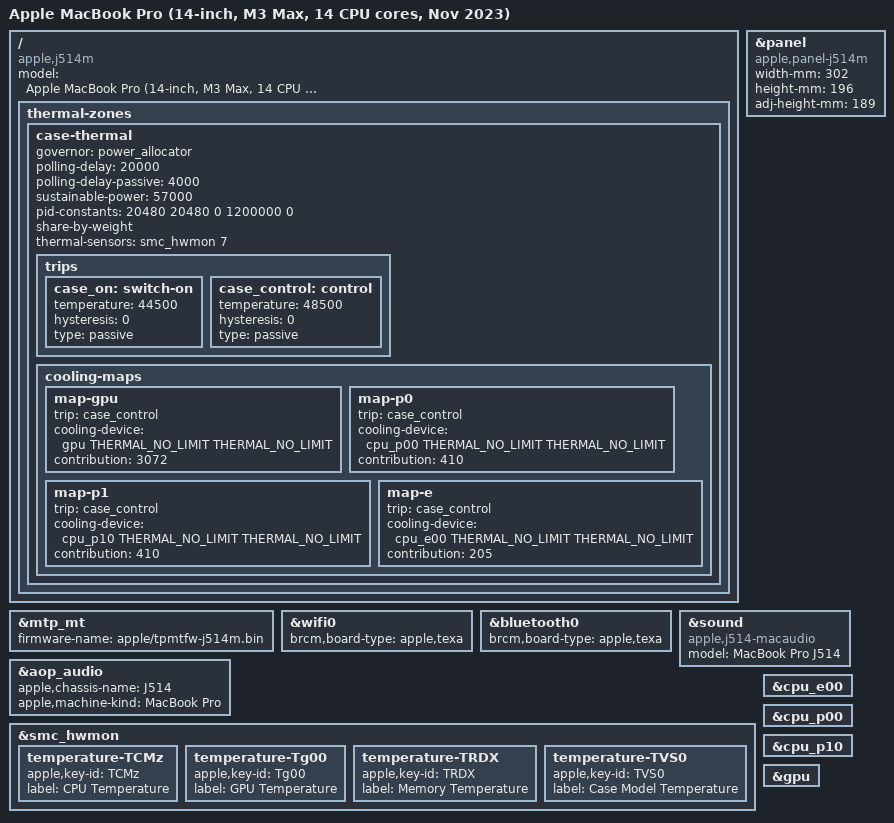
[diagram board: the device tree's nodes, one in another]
// SPDX-License-Identifier: GPL-2.0+ OR MIT
/*
 * MacBook Pro (14-inch, M3 Max, 14 CPU cores, Nov 2023)
 *
 * target-type: J514m
 *
 * Copyright The Asahi Linux Contributors
 */

/dts-v1/;

#include <dt-bindings/thermal/thermal.h>
#include "t6034.dtsi"
#include "t603x-j514-j516.dtsi"
#include "t6031-j514-j516.dtsi"

/ {
	compatible = "apple,j514m", "apple,t6034", "apple,arm-platform";
	model = "Apple MacBook Pro (14-inch, M3 Max, 14 CPU cores, Nov 2023)";
};

&panel {
	compatible = "apple,panel-j514m", "apple,panel-mini-led", "apple,panel";
	width-mm = <302>;
	height-mm = <196>;
	adj-height-mm = <189>;
};

&mtp_mt {
	firmware-name = "apple/tpmtfw-j514m.bin";
};

&wifi0 {
	brcm,board-type = "apple,texa";
};

&bluetooth0 {
	brcm,board-type = "apple,texa";
};

&aop_audio {
	apple,chassis-name = "J514";
	apple,machine-kind = "MacBook Pro";
};

&sound {
	compatible = "apple,j514-macaudio", "apple,j314-macaudio", "apple,macaudio";
	model = "MacBook Pro J514";
};

&smc_hwmon {
	#thermal-sensor-cells = <1>;

	/*
	 * The CPU's and the GPU's temperatures (read on this Mac, 2026-11-02):
	 * TCMz follows the P cores (+16 C for one busy core, +24 C for all ten)
	 * and sits above every P-core die sensor (Tp**), so the clusters' max
	 * (inferred); Tg00 is the first of the GPU die's 16 sensor pairs, 0 while
	 * the GPU is powered off, 61-64 C with every pair under a GPU load.
	 */
	temperature-TCMz {
		apple,key-id = "TCMz";
		label = "CPU Temperature";
	};

	temperature-Tg00 {
		apple,key-id = "Tg00";
		label = "GPU Temperature";
	};

	/*
	 * The hottest of the memory's sensors, and the SMC's model of the case
	 * (read as such; it lags the fast sensors by about 200 s). The SMC slows
	 * the GPU to 618 MHz and the whole Mac to about 33 W when TVS0 reaches
	 * 50.00 C, and lets go below 49.97 C, about a minute later under load.
	 */
	temperature-TRDX {
		apple,key-id = "TRDX";
		label = "Memory Temperature";
	};

	temperature-TVS0 {
		apple,key-id = "TVS0";
		label = "Case Model Temperature";
	};
};

&cpu_e00 {
	#cooling-cells = <2>;
};

&cpu_p00 {
	#cooling-cells = <2>;
};

&cpu_p10 {
	#cooling-cells = <2>;
};

&gpu {
	#cooling-cells = <2>;
};

/ {
	thermal-zones {
		/*
		 * Hold the case model under the SMC's 50 C line. The budget is shared by
		 * weight alone, the GPU's weight by its cost at the wall: its cooling
		 * states count about 2.4 W of the system's for each watt of its own.
		 */
		case-thermal {
			governor = "power_allocator";
			polling-delay = <20000>;
			polling-delay-passive = <4000>;
			sustainable-power = <57000>;
			pid-constants = <20480 20480 0 1200000 0>;
			share-by-weight;
			thermal-sensors = <&smc_hwmon 7>;

			trips {
				case_on: switch-on {
					temperature = <44500>;
					hysteresis = <0>;
					type = "passive";
				};

				case_control: control {
					temperature = <48500>;
					hysteresis = <0>;
					type = "passive";
				};
			};

			cooling-maps {
				map-gpu {
					trip = <&case_control>;
					cooling-device = <&gpu THERMAL_NO_LIMIT THERMAL_NO_LIMIT>;
					contribution = <3072>;
				};

				map-p0 {
					trip = <&case_control>;
					cooling-device = <&cpu_p00 THERMAL_NO_LIMIT THERMAL_NO_LIMIT>;
					contribution = <410>;
				};

				map-p1 {
					trip = <&case_control>;
					cooling-device = <&cpu_p10 THERMAL_NO_LIMIT THERMAL_NO_LIMIT>;
					contribution = <410>;
				};

				map-e {
					trip = <&case_control>;
					cooling-device = <&cpu_e00 THERMAL_NO_LIMIT THERMAL_NO_LIMIT>;
					contribution = <205>;
				};
			};
		};
	};
};
